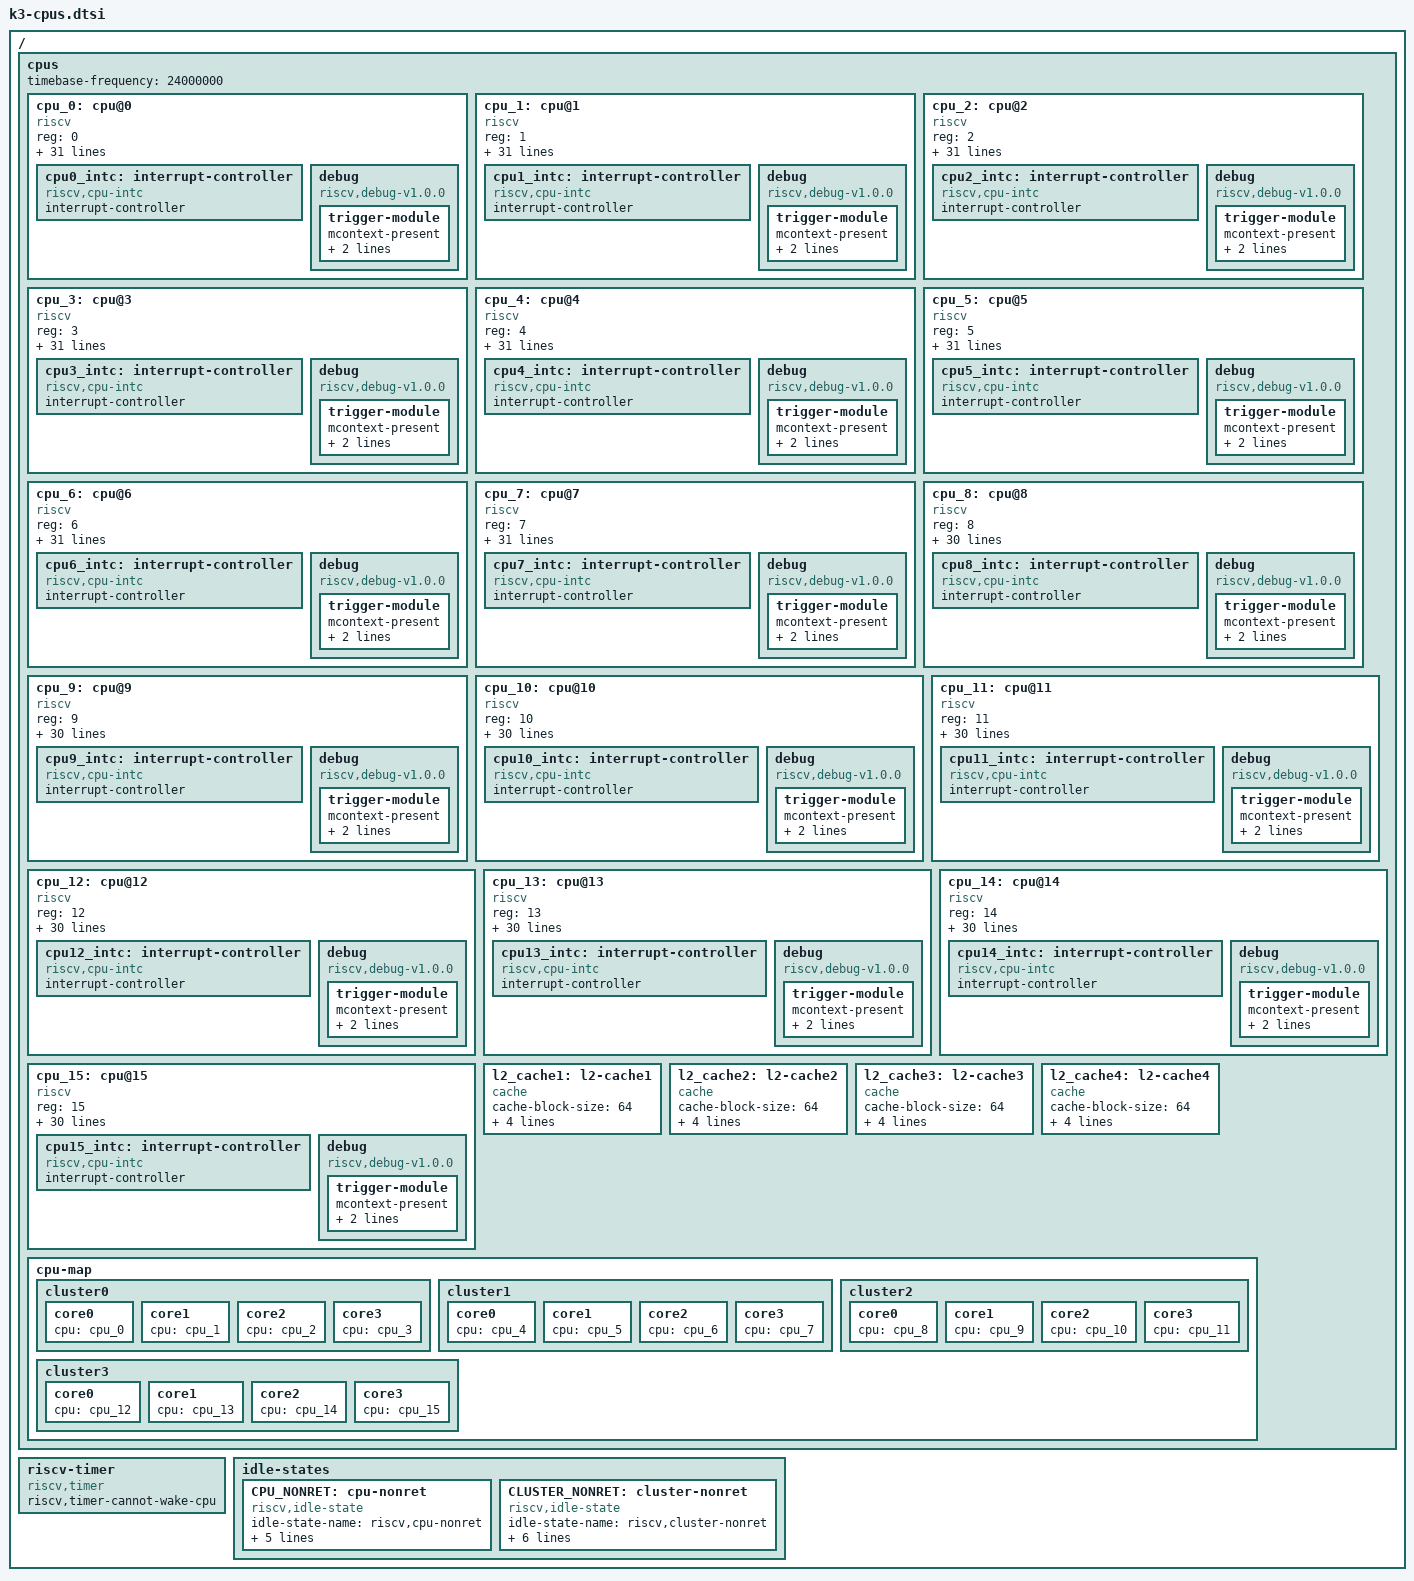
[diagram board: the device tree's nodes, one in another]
/ {
	cpus: cpus {
			#address-cells = <1>;
			#size-cells = <0>;
			timebase-frequency = <24000000>;

			cpu_0: cpu@0 {
				device_type = "cpu";
				reg = <0>;
				model = "Spacemit(R) X100";
				status = "okay";
				compatible = "riscv";
				riscv,isa = "rv64imafdcvh";
				riscv,isa-base = "rv64i";
				riscv,isa-extensions = "i", "m", "a", "f", "d", "c", "b", "v", "h",
						       "sdtrig",
						       "sha", "shcounterenw", "shgatpa", "shtvala",
						       "shvsatpa", "shvstvala", "shvstvecd", "smaia",
						       "smstateen", "ssaia", "ssccptr", "sscofpmf",
						       "sscounterenw", "ssnpm", "ssstateen", "sstc",
						       "sstvala", "sstvecd", "ssu64xl", "svade",
						       "svinval", "svnapot", "svpbmt", "za64rs",
						       "zawrs", "zba", "zbb", "zbc", "zbs", "zca",
						       "zcb", "zcd", "zcmop", "zfa", "zfbfmin",
						       "zfh", "zfhmin", "zicbom", "zicbop", "zicboz",
						       "ziccamoa", "ziccif", "zicclsm", "zicntr",
						       "zicond", "zicsr", "zifencei", "zihintntl",
						       "zihintpause", "zihpm", "zimop", "zkt", "zvbb",
						       "zvbc", "zvfbfmin", "zvfbfwma", "zvfh",
						       "zvfhmin", "zvkb", "zvkg", "zvkn", "zvknc",
						       "zvkned", "zvkng", "zvknha", "zvknhb", "zvks",
						       "zvksc", "zvksed", "zvksg", "zvksh", "zvkt";
				riscv,cbom-block-size = <64>;
				riscv,cboz-block-size = <64>;
				riscv,cbop-block-size = <64>;
				i-cache-block-size = <64>;
				i-cache-size = <65536>;
				i-cache-sets = <256>;
				d-cache-block-size = <64>;
				d-cache-size = <65536>;
				d-cache-sets = <256>;
				next-level-cache = <&l2_cache1>;
				cpu-idle-states = <&CPU_NONRET>, <&CLUSTER_NONRET>;
				mmu-type = "riscv,sv39";
				#cooling-cells = <2>;
				cpu0_intc: interrupt-controller {
					#interrupt-cells = <1>;
					compatible = "riscv,cpu-intc";
					interrupt-controller;
				};
				debug {
					compatible = "riscv,debug-v1.0.0";
					trigger-module {
						mcontext-present;
						hcontext-present;
						scontext-present;
					};
				};
			};

			cpu_1: cpu@1 {
				device_type = "cpu";
				reg = <1>;
				model = "Spacemit(R) X100";
				status = "okay";
				compatible = "riscv";
				riscv,isa = "rv64imafdcvh";
				riscv,isa-base = "rv64i";
				riscv,isa-extensions = "i", "m", "a", "f", "d", "c", "b", "v", "h",
						       "sdtrig",
						       "sha", "shcounterenw", "shgatpa", "shtvala",
						       "shvsatpa", "shvstvala", "shvstvecd", "smaia",
						       "smstateen", "ssaia", "ssccptr", "sscofpmf",
						       "sscounterenw", "ssnpm", "ssstateen", "sstc",
						       "sstvala", "sstvecd", "ssu64xl", "svade",
						       "svinval", "svnapot", "svpbmt", "za64rs",
						       "zawrs", "zba", "zbb", "zbc", "zbs", "zca",
						       "zcb", "zcd", "zcmop", "zfa", "zfbfmin",
						       "zfh", "zfhmin", "zicbom", "zicbop", "zicboz",
						       "ziccamoa", "ziccif", "zicclsm", "zicntr",
						       "zicond", "zicsr", "zifencei", "zihintntl",
						       "zihintpause", "zihpm", "zimop", "zkt", "zvbb",
						       "zvbc", "zvfbfmin", "zvfbfwma", "zvfh",
						       "zvfhmin", "zvkb", "zvkg", "zvkn", "zvknc",
						       "zvkned", "zvkng", "zvknha", "zvknhb", "zvks",
						       "zvksc", "zvksed", "zvksg", "zvksh", "zvkt";
				riscv,cbom-block-size = <64>;
				riscv,cboz-block-size = <64>;
				riscv,cbop-block-size = <64>;
				i-cache-block-size = <64>;
				i-cache-size = <65536>;
				i-cache-sets = <256>;
				d-cache-block-size = <64>;
				d-cache-size = <65536>;
				d-cache-sets = <256>;
				next-level-cache = <&l2_cache1>;
				cpu-idle-states = <&CPU_NONRET>, <&CLUSTER_NONRET>;
				mmu-type = "riscv,sv39";
				#cooling-cells = <2>;
				cpu1_intc: interrupt-controller {
					#interrupt-cells = <1>;
					compatible = "riscv,cpu-intc";
					interrupt-controller;
				};
				debug {
					compatible = "riscv,debug-v1.0.0";
					trigger-module {
						mcontext-present;
						hcontext-present;
						scontext-present;
					};
				};
			};

			cpu_2: cpu@2 {
				device_type = "cpu";
				reg = <2>;
				model = "Spacemit(R) X100";
				status = "okay";
				compatible = "riscv";
				riscv,isa = "rv64imafdcvh";
				riscv,isa-base = "rv64i";
				riscv,isa-extensions = "i", "m", "a", "f", "d", "c", "b", "v", "h",
						       "sdtrig",
						       "sha", "shcounterenw", "shgatpa", "shtvala",
						       "shvsatpa", "shvstvala", "shvstvecd", "smaia",
						       "smstateen", "ssaia", "ssccptr", "sscofpmf",
						       "sscounterenw", "ssnpm", "ssstateen", "sstc",
						       "sstvala", "sstvecd", "ssu64xl", "svade",
						       "svinval", "svnapot", "svpbmt", "za64rs",
						       "zawrs", "zba", "zbb", "zbc", "zbs", "zca",
						       "zcb", "zcd", "zcmop", "zfa", "zfbfmin",
						       "zfh", "zfhmin", "zicbom", "zicbop", "zicboz",
						       "ziccamoa", "ziccif", "zicclsm", "zicntr",
						       "zicond", "zicsr", "zifencei", "zihintntl",
						       "zihintpause", "zihpm", "zimop", "zkt", "zvbb",
						       "zvbc", "zvfbfmin", "zvfbfwma", "zvfh",
						       "zvfhmin", "zvkb", "zvkg", "zvkn", "zvknc",
						       "zvkned", "zvkng", "zvknha", "zvknhb", "zvks",
						       "zvksc", "zvksed", "zvksg", "zvksh", "zvkt";
				riscv,cbom-block-size = <64>;
				riscv,cboz-block-size = <64>;
				riscv,cbop-block-size = <64>;
				i-cache-block-size = <64>;
				i-cache-size = <65536>;
				i-cache-sets = <256>;
				d-cache-block-size = <64>;
				d-cache-size = <65536>;
				d-cache-sets = <256>;
				next-level-cache = <&l2_cache1>;
				cpu-idle-states = <&CPU_NONRET>, <&CLUSTER_NONRET>;
				mmu-type = "riscv,sv39";
				#cooling-cells = <2>;
				cpu2_intc: interrupt-controller {
					#interrupt-cells = <1>;
					compatible = "riscv,cpu-intc";
					interrupt-controller;
				};
				debug {
					compatible = "riscv,debug-v1.0.0";
					trigger-module {
						mcontext-present;
						hcontext-present;
						scontext-present;
					};
				};
			};

			cpu_3: cpu@3 {
				device_type = "cpu";
				reg = <3>;
				model = "Spacemit(R) X100";
				status = "okay";
				compatible = "riscv";
				riscv,isa = "rv64imafdcvh";
				riscv,isa-base = "rv64i";
				riscv,isa-extensions = "i", "m", "a", "f", "d", "c", "b", "v", "h",
						       "sdtrig",
						       "sha", "shcounterenw", "shgatpa", "shtvala",
						       "shvsatpa", "shvstvala", "shvstvecd", "smaia",
						       "smstateen", "ssaia", "ssccptr", "sscofpmf",
						       "sscounterenw", "ssnpm", "ssstateen", "sstc",
						       "sstvala", "sstvecd", "ssu64xl", "svade",
						       "svinval", "svnapot", "svpbmt", "za64rs",
						       "zawrs", "zba", "zbb", "zbc", "zbs", "zca",
						       "zcb", "zcd", "zcmop", "zfa", "zfbfmin",
						       "zfh", "zfhmin", "zicbom", "zicbop", "zicboz",
						       "ziccamoa", "ziccif", "zicclsm", "zicntr",
						       "zicond", "zicsr", "zifencei", "zihintntl",
						       "zihintpause", "zihpm", "zimop", "zkt", "zvbb",
						       "zvbc", "zvfbfmin", "zvfbfwma", "zvfh",
						       "zvfhmin", "zvkb", "zvkg", "zvkn", "zvknc",
						       "zvkned", "zvkng", "zvknha", "zvknhb", "zvks",
						       "zvksc", "zvksed", "zvksg", "zvksh", "zvkt";
				riscv,cbom-block-size = <64>;
				riscv,cboz-block-size = <64>;
				riscv,cbop-block-size = <64>;
				i-cache-block-size = <64>;
				i-cache-size = <65536>;
				i-cache-sets = <256>;
				d-cache-block-size = <64>;
				d-cache-size = <65536>;
				d-cache-sets = <256>;
				next-level-cache = <&l2_cache1>;
				cpu-idle-states = <&CPU_NONRET>, <&CLUSTER_NONRET>;
				mmu-type = "riscv,sv39";
				#cooling-cells = <2>;
				cpu3_intc: interrupt-controller {
					#interrupt-cells = <1>;
					compatible = "riscv,cpu-intc";
					interrupt-controller;
				};
				debug {
					compatible = "riscv,debug-v1.0.0";
					trigger-module {
						mcontext-present;
						hcontext-present;
						scontext-present;
					};
				};
			};

			cpu_4: cpu@4 {
				device_type = "cpu";
				reg = <4>;
				model = "Spacemit(R) X100";
				status = "okay";
				compatible = "riscv";
				riscv,isa = "rv64imafdcvh";
				riscv,isa-base = "rv64i";
				riscv,isa-extensions = "i", "m", "a", "f", "d", "c", "b", "v", "h",
						       "sdtrig",
						       "sha", "shcounterenw", "shgatpa", "shtvala",
						       "shvsatpa", "shvstvala", "shvstvecd", "smaia",
						       "smstateen", "ssaia", "ssccptr", "sscofpmf",
						       "sscounterenw", "ssnpm", "ssstateen", "sstc",
						       "sstvala", "sstvecd", "ssu64xl", "svade",
						       "svinval", "svnapot", "svpbmt", "za64rs",
						       "zawrs", "zba", "zbb", "zbc", "zbs", "zca",
						       "zcb", "zcd", "zcmop", "zfa", "zfbfmin",
						       "zfh", "zfhmin", "zicbom", "zicbop", "zicboz",
						       "ziccamoa", "ziccif", "zicclsm", "zicntr",
						       "zicond", "zicsr", "zifencei", "zihintntl",
						       "zihintpause", "zihpm", "zimop", "zkt", "zvbb",
						       "zvbc", "zvfbfmin", "zvfbfwma", "zvfh",
						       "zvfhmin", "zvkb", "zvkg", "zvkn", "zvknc",
						       "zvkned", "zvkng", "zvknha", "zvknhb", "zvks",
						       "zvksc", "zvksed", "zvksg", "zvksh", "zvkt";
				riscv,cbom-block-size = <64>;
				riscv,cboz-block-size = <64>;
				riscv,cbop-block-size = <64>;
				i-cache-block-size = <64>;
				i-cache-size = <65536>;
				i-cache-sets = <256>;
				d-cache-block-size = <64>;
				d-cache-size = <65536>;
				d-cache-sets = <256>;
				next-level-cache = <&l2_cache2>;
				cpu-idle-states = <&CPU_NONRET>, <&CLUSTER_NONRET>;
				mmu-type = "riscv,sv39";
				#cooling-cells = <2>;
				cpu4_intc: interrupt-controller {
					#interrupt-cells = <1>;
					compatible = "riscv,cpu-intc";
					interrupt-controller;
				};
				debug {
					compatible = "riscv,debug-v1.0.0";
					trigger-module {
						mcontext-present;
						hcontext-present;
						scontext-present;
					};
				};
			};

			cpu_5: cpu@5 {
				device_type = "cpu";
				reg = <5>;
				model = "Spacemit(R) X100";
				status = "okay";
				compatible = "riscv";
				riscv,isa = "rv64imafdcvh";
				riscv,isa-base = "rv64i";
				riscv,isa-extensions = "i", "m", "a", "f", "d", "c", "b", "v", "h",
						       "sdtrig",
						       "sha", "shcounterenw", "shgatpa", "shtvala",
						       "shvsatpa", "shvstvala", "shvstvecd", "smaia",
						       "smstateen", "ssaia", "ssccptr", "sscofpmf",
						       "sscounterenw", "ssnpm", "ssstateen", "sstc",
						       "sstvala", "sstvecd", "ssu64xl", "svade",
						       "svinval", "svnapot", "svpbmt", "za64rs",
						       "zawrs", "zba", "zbb", "zbc", "zbs", "zca",
						       "zcb", "zcd", "zcmop", "zfa", "zfbfmin",
						       "zfh", "zfhmin", "zicbom", "zicbop", "zicboz",
						       "ziccamoa", "ziccif", "zicclsm", "zicntr",
						       "zicond", "zicsr", "zifencei", "zihintntl",
						       "zihintpause", "zihpm", "zimop", "zkt", "zvbb",
						       "zvbc", "zvfbfmin", "zvfbfwma", "zvfh",
						       "zvfhmin", "zvkb", "zvkg", "zvkn", "zvknc",
						       "zvkned", "zvkng", "zvknha", "zvknhb", "zvks",
						       "zvksc", "zvksed", "zvksg", "zvksh", "zvkt";
				riscv,cbom-block-size = <64>;
				riscv,cboz-block-size = <64>;
				riscv,cbop-block-size = <64>;
				i-cache-block-size = <64>;
				i-cache-size = <65536>;
				i-cache-sets = <256>;
				d-cache-block-size = <64>;
				d-cache-size = <65536>;
				d-cache-sets = <256>;
				next-level-cache = <&l2_cache2>;
				cpu-idle-states = <&CPU_NONRET>, <&CLUSTER_NONRET>;
				mmu-type = "riscv,sv39";
				#cooling-cells = <2>;
				cpu5_intc: interrupt-controller {
					#interrupt-cells = <1>;
					compatible = "riscv,cpu-intc";
					interrupt-controller;
				};
				debug {
					compatible = "riscv,debug-v1.0.0";
					trigger-module {
						mcontext-present;
						hcontext-present;
						scontext-present;
					};
				};
			};

			cpu_6: cpu@6 {
				device_type = "cpu";
				reg = <6>;
				model = "Spacemit(R) X100";
				status = "okay";
				compatible = "riscv";
				riscv,isa = "rv64imafdcvh";
				riscv,isa-base = "rv64i";
				riscv,isa-extensions = "i", "m", "a", "f", "d", "c", "b", "v", "h",
						       "sdtrig",
						       "sha", "shcounterenw", "shgatpa", "shtvala",
						       "shvsatpa", "shvstvala", "shvstvecd", "smaia",
						       "smstateen", "ssaia", "ssccptr", "sscofpmf",
						       "sscounterenw", "ssnpm", "ssstateen", "sstc",
						       "sstvala", "sstvecd", "ssu64xl", "svade",
						       "svinval", "svnapot", "svpbmt", "za64rs",
						       "zawrs", "zba", "zbb", "zbc", "zbs", "zca",
						       "zcb", "zcd", "zcmop", "zfa", "zfbfmin",
						       "zfh", "zfhmin", "zicbom", "zicbop", "zicboz",
						       "ziccamoa", "ziccif", "zicclsm", "zicntr",
						       "zicond", "zicsr", "zifencei", "zihintntl",
						       "zihintpause", "zihpm", "zimop", "zkt", "zvbb",
						       "zvbc", "zvfbfmin", "zvfbfwma", "zvfh",
						       "zvfhmin", "zvkb", "zvkg", "zvkn", "zvknc",
						       "zvkned", "zvkng", "zvknha", "zvknhb", "zvks",
						       "zvksc", "zvksed", "zvksg", "zvksh", "zvkt";
				riscv,cbom-block-size = <64>;
				riscv,cboz-block-size = <64>;
				riscv,cbop-block-size = <64>;
				i-cache-block-size = <64>;
				i-cache-size = <65536>;
				i-cache-sets = <256>;
				d-cache-block-size = <64>;
				d-cache-size = <65536>;
				d-cache-sets = <256>;
				next-level-cache = <&l2_cache2>;
				cpu-idle-states = <&CPU_NONRET>, <&CLUSTER_NONRET>;
				mmu-type = "riscv,sv39";
				#cooling-cells = <2>;
				cpu6_intc: interrupt-controller {
					#interrupt-cells = <1>;
					compatible = "riscv,cpu-intc";
					interrupt-controller;
				};
				debug {
					compatible = "riscv,debug-v1.0.0";
					trigger-module {
						mcontext-present;
						hcontext-present;
						scontext-present;
					};
				};
			};

			cpu_7: cpu@7 {
				device_type = "cpu";
				reg = <7>;
				model = "Spacemit(R) X100";
				status = "okay";
				compatible = "riscv";
				riscv,isa = "rv64imafdcvh";
				riscv,isa-base = "rv64i";
				riscv,isa-extensions = "i", "m", "a", "f", "d", "c", "b", "v", "h",
						       "sdtrig",
						       "sha", "shcounterenw", "shgatpa", "shtvala",
						       "shvsatpa", "shvstvala", "shvstvecd", "smaia",
						       "smstateen", "ssaia", "ssccptr", "sscofpmf",
						       "sscounterenw", "ssnpm", "ssstateen", "sstc",
						       "sstvala", "sstvecd", "ssu64xl", "svade",
						       "svinval", "svnapot", "svpbmt", "za64rs",
						       "zawrs", "zba", "zbb", "zbc", "zbs", "zca",
						       "zcb", "zcd", "zcmop", "zfa", "zfbfmin",
						       "zfh", "zfhmin", "zicbom", "zicbop", "zicboz",
						       "ziccamoa", "ziccif", "zicclsm", "zicntr",
						       "zicond", "zicsr", "zifencei", "zihintntl",
						       "zihintpause", "zihpm", "zimop", "zkt", "zvbb",
						       "zvbc", "zvfbfmin", "zvfbfwma", "zvfh",
						       "zvfhmin", "zvkb", "zvkg", "zvkn", "zvknc",
						       "zvkned", "zvkng", "zvknha", "zvknhb", "zvks",
						       "zvksc", "zvksed", "zvksg", "zvksh", "zvkt";
				riscv,cbom-block-size = <64>;
				riscv,cboz-block-size = <64>;
				riscv,cbop-block-size = <64>;
				i-cache-block-size = <64>;
				i-cache-size = <65536>;
				i-cache-sets = <256>;
				d-cache-block-size = <64>;
				d-cache-size = <65536>;
				d-cache-sets = <256>;
				next-level-cache = <&l2_cache2>;
				cpu-idle-states = <&CPU_NONRET>, <&CLUSTER_NONRET>;
				mmu-type = "riscv,sv39";
				#cooling-cells = <2>;
				cpu7_intc: interrupt-controller {
					#interrupt-cells = <1>;
					compatible = "riscv,cpu-intc";
					interrupt-controller;
				};
				debug {
					compatible = "riscv,debug-v1.0.0";
					trigger-module {
						mcontext-present;
						hcontext-present;
						scontext-present;
					};
				};
			};

			cpu_8: cpu@8 {
				device_type = "cpu";
				reg = <8>;
				model = "Spacemit(R) A100";
				status = "okay";
				compatible = "riscv";
				cpu-ai = "true";
				riscv,isa = "rv64imafdcv";
				riscv,isa-base = "rv64i";
				riscv,isa-extensions = "i", "m", "a", "f", "d", "c", "b", "v",
						       "sdtrig", "smaia",
						       "smstateen", "ssaia", "ssccptr", "sscofpmf",
						       "sscounterenw", "ssnpm", "ssstateen", "sstc",
						       "sstvala", "sstvecd", "ssu64xl", "svade",
						       "svinval", "svnapot", "svpbmt", "za64rs",
						       "zawrs", "zba", "zbb", "zbc", "zbs", "zca",
						       "zcb", "zcd", "zcmop", "zfa", "zfbfmin",
						       "zfh", "zfhmin", "zicbom", "zicbop", "zicboz",
						       "ziccamoa", "ziccif", "zicclsm", "zicntr",
						       "zicond", "zicsr", "zifencei", "zihintntl",
						       "zihintpause", "zihpm", "zimop", "zkt", "zvbb",
						       "zvbc", "zvfbfmin", "zvfbfwma", "zvfh",
						       "zvfhmin", "zvkb", "zvkg", "zvkn", "zvknc",
						       "zvkned", "zvkng", "zvknha", "zvknhb", "zvks",
						       "zvksc", "zvksed", "zvksg", "zvksh", "zvkt";
				riscv,cbom-block-size = <64>;
				riscv,cboz-block-size = <64>;
				riscv,cbop-block-size = <64>;
				i-cache-block-size = <64>;
				i-cache-size = <65536>;
				i-cache-sets = <256>;
				d-cache-block-size = <64>;
				d-cache-size = <65536>;
				d-cache-sets = <256>;
				next-level-cache = <&l2_cache3>;
				cpu-idle-states = <&CPU_NONRET>, <&CLUSTER_NONRET>;
				mmu-type = "riscv,sv39";
				#cooling-cells = <2>;
				cpu8_intc: interrupt-controller {
					#interrupt-cells = <1>;
					compatible = "riscv,cpu-intc";
					interrupt-controller;
				};
				debug {
					compatible = "riscv,debug-v1.0.0";
					trigger-module {
						mcontext-present;
						hcontext-present;
						scontext-present;
					};
				};
			};

			cpu_9: cpu@9 {
				device_type = "cpu";
				reg = <9>;
				model = "Spacemit(R) A100";
				status = "okay";
				compatible = "riscv";
				cpu-ai = "true";
				riscv,isa = "rv64imafdcv";
				riscv,isa-base = "rv64i";
				riscv,isa-extensions = "i", "m", "a", "f", "d", "c", "b", "v",
						       "sdtrig", "smaia",
						       "smstateen", "ssaia", "ssccptr", "sscofpmf",
						       "sscounterenw", "ssnpm", "ssstateen", "sstc",
						       "sstvala", "sstvecd", "ssu64xl", "svade",
						       "svinval", "svnapot", "svpbmt", "za64rs",
						       "zawrs", "zba", "zbb", "zbc", "zbs", "zca",
						       "zcb", "zcd", "zcmop", "zfa", "zfbfmin",
						       "zfh", "zfhmin", "zicbom", "zicbop", "zicboz",
						       "ziccamoa", "ziccif", "zicclsm", "zicntr",
						       "zicond", "zicsr", "zifencei", "zihintntl",
						       "zihintpause", "zihpm", "zimop", "zkt", "zvbb",
						       "zvbc", "zvfbfmin", "zvfbfwma", "zvfh",
						       "zvfhmin", "zvkb", "zvkg", "zvkn", "zvknc",
						       "zvkned", "zvkng", "zvknha", "zvknhb", "zvks",
						       "zvksc", "zvksed", "zvksg", "zvksh", "zvkt";
				riscv,cbom-block-size = <64>;
				riscv,cboz-block-size = <64>;
				riscv,cbop-block-size = <64>;
				i-cache-block-size = <64>;
				i-cache-size = <65536>;
				i-cache-sets = <256>;
				d-cache-block-size = <64>;
				d-cache-size = <65536>;
				d-cache-sets = <256>;
				next-level-cache = <&l2_cache3>;
				cpu-idle-states = <&CPU_NONRET>, <&CLUSTER_NONRET>;
				mmu-type = "riscv,sv39";
				#cooling-cells = <2>;
				cpu9_intc: interrupt-controller {
					#interrupt-cells = <1>;
					compatible = "riscv,cpu-intc";
					interrupt-controller;
				};
				debug {
					compatible = "riscv,debug-v1.0.0";
					trigger-module {
						mcontext-present;
						hcontext-present;
						scontext-present;
					};
				};
			};

			cpu_10: cpu@10 {
				device_type = "cpu";
				reg = <10>;
				model = "Spacemit(R) A100";
				status = "okay";
				compatible = "riscv";
				cpu-ai = "true";
				riscv,isa = "rv64imafdcv";
				riscv,isa-base = "rv64i";
				riscv,isa-extensions = "i", "m", "a", "f", "d", "c", "b", "v",
						       "sdtrig", "smaia",
						       "smstateen", "ssaia", "ssccptr", "sscofpmf",
						       "sscounterenw", "ssnpm", "ssstateen", "sstc",
						       "sstvala", "sstvecd", "ssu64xl", "svade",
						       "svinval", "svnapot", "svpbmt", "za64rs",
						       "zawrs", "zba", "zbb", "zbc", "zbs", "zca",
						       "zcb", "zcd", "zcmop", "zfa", "zfbfmin",
						       "zfh", "zfhmin", "zicbom", "zicbop", "zicboz",
						       "ziccamoa", "ziccif", "zicclsm", "zicntr",
						       "zicond", "zicsr", "zifencei", "zihintntl",
						       "zihintpause", "zihpm", "zimop", "zkt", "zvbb",
						       "zvbc", "zvfbfmin", "zvfbfwma", "zvfh",
						       "zvfhmin", "zvkb", "zvkg", "zvkn", "zvknc",
						       "zvkned", "zvkng", "zvknha", "zvknhb", "zvks",
						       "zvksc", "zvksed", "zvksg", "zvksh", "zvkt";
				riscv,cbom-block-size = <64>;
				riscv,cboz-block-size = <64>;
				riscv,cbop-block-size = <64>;
				i-cache-block-size = <64>;
				i-cache-size = <65536>;
				i-cache-sets = <256>;
				d-cache-block-size = <64>;
				d-cache-size = <65536>;
				d-cache-sets = <256>;
				next-level-cache = <&l2_cache3>;
				cpu-idle-states = <&CPU_NONRET>, <&CLUSTER_NONRET>;
				mmu-type = "riscv,sv39";
				#cooling-cells = <2>;
				cpu10_intc: interrupt-controller {
					#interrupt-cells = <1>;
					compatible = "riscv,cpu-intc";
					interrupt-controller;
				};
				debug {
					compatible = "riscv,debug-v1.0.0";
					trigger-module {
						mcontext-present;
						hcontext-present;
						scontext-present;
					};
				};
			};

			cpu_11: cpu@11 {
				device_type = "cpu";
				reg = <11>;
				model = "Spacemit(R) A100";
				status = "okay";
				compatible = "riscv";
				cpu-ai = "true";
				riscv,isa = "rv64imafdcv";
				riscv,isa-base = "rv64i";
				riscv,isa-extensions = "i", "m", "a", "f", "d", "c", "b", "v",
						       "sdtrig", "smaia",
						       "smstateen", "ssaia", "ssccptr", "sscofpmf",
						       "sscounterenw", "ssnpm", "ssstateen", "sstc",
						       "sstvala", "sstvecd", "ssu64xl", "svade",
						       "svinval", "svnapot", "svpbmt", "za64rs",
						       "zawrs", "zba", "zbb", "zbc", "zbs", "zca",
						       "zcb", "zcd", "zcmop", "zfa", "zfbfmin",
						       "zfh", "zfhmin", "zicbom", "zicbop", "zicboz",
						       "ziccamoa", "ziccif", "zicclsm", "zicntr",
						       "zicond", "zicsr", "zifencei", "zihintntl",
						       "zihintpause", "zihpm", "zimop", "zkt", "zvbb",
						       "zvbc", "zvfbfmin", "zvfbfwma", "zvfh",
						       "zvfhmin", "zvkb", "zvkg", "zvkn", "zvknc",
						       "zvkned", "zvkng", "zvknha", "zvknhb", "zvks",
						       "zvksc", "zvksed", "zvksg", "zvksh", "zvkt";
				riscv,cbom-block-size = <64>;
				riscv,cboz-block-size = <64>;
				riscv,cbop-block-size = <64>;
				i-cache-block-size = <64>;
				i-cache-size = <65536>;
				i-cache-sets = <256>;
				d-cache-block-size = <64>;
				d-cache-size = <65536>;
				d-cache-sets = <256>;
				next-level-cache = <&l2_cache3>;
				cpu-idle-states = <&CPU_NONRET>, <&CLUSTER_NONRET>;
				mmu-type = "riscv,sv39";
				#cooling-cells = <2>;
				cpu11_intc: interrupt-controller {
					#interrupt-cells = <1>;
					compatible = "riscv,cpu-intc";
					interrupt-controller;
				};
				debug {
					compatible = "riscv,debug-v1.0.0";
					trigger-module {
						mcontext-present;
						hcontext-present;
						scontext-present;
					};
				};
			};

			cpu_12: cpu@12 {
				device_type = "cpu";
				reg = <12>;
				model = "Spacemit(R) A100";
				status = "okay";
				compatible = "riscv";
				cpu-ai = "true";
				riscv,isa = "rv64imafdcv";
				riscv,isa-base = "rv64i";
				riscv,isa-extensions = "i", "m", "a", "f", "d", "c", "b", "v",
						       "sdtrig", "smaia",
						       "smstateen", "ssaia", "ssccptr", "sscofpmf",
						       "sscounterenw", "ssnpm", "ssstateen", "sstc",
						       "sstvala", "sstvecd", "ssu64xl", "svade",
						       "svinval", "svnapot", "svpbmt", "za64rs",
						       "zawrs", "zba", "zbb", "zbc", "zbs", "zca",
						       "zcb", "zcd", "zcmop", "zfa", "zfbfmin",
						       "zfh", "zfhmin", "zicbom", "zicbop", "zicboz",
						       "ziccamoa", "ziccif", "zicclsm", "zicntr",
						       "zicond", "zicsr", "zifencei", "zihintntl",
						       "zihintpause", "zihpm", "zimop", "zkt", "zvbb",
						       "zvbc", "zvfbfmin", "zvfbfwma", "zvfh",
						       "zvfhmin", "zvkb", "zvkg", "zvkn", "zvknc",
						       "zvkned", "zvkng", "zvknha", "zvknhb", "zvks",
						       "zvksc", "zvksed", "zvksg", "zvksh", "zvkt";
				riscv,cbom-block-size = <64>;
				riscv,cboz-block-size = <64>;
				riscv,cbop-block-size = <64>;
				i-cache-block-size = <64>;
				i-cache-size = <65536>;
				i-cache-sets = <256>;
				d-cache-block-size = <64>;
				d-cache-size = <65536>;
				d-cache-sets = <256>;
				next-level-cache = <&l2_cache4>;
				cpu-idle-states = <&CPU_NONRET>, <&CLUSTER_NONRET>;
				mmu-type = "riscv,sv39";
				#cooling-cells = <2>;
				cpu12_intc: interrupt-controller {
					#interrupt-cells = <1>;
					compatible = "riscv,cpu-intc";
					interrupt-controller;
				};
				debug {
					compatible = "riscv,debug-v1.0.0";
					trigger-module {
						mcontext-present;
						hcontext-present;
						scontext-present;
					};
				};
			};

			cpu_13: cpu@13 {
				device_type = "cpu";
				reg = <13>;
				model = "Spacemit(R) A100";
				status = "okay";
				compatible = "riscv";
				cpu-ai = "true";
				riscv,isa = "rv64imafdcv";
				riscv,isa-base = "rv64i";
				riscv,isa-extensions = "i", "m", "a", "f", "d", "c", "b", "v",
						       "sdtrig", "smaia",
						       "smstateen", "ssaia", "ssccptr", "sscofpmf",
						       "sscounterenw", "ssnpm", "ssstateen", "sstc",
						       "sstvala", "sstvecd", "ssu64xl", "svade",
						       "svinval", "svnapot", "svpbmt", "za64rs",
						       "zawrs", "zba", "zbb", "zbc", "zbs", "zca",
						       "zcb", "zcd", "zcmop", "zfa", "zfbfmin",
						       "zfh", "zfhmin", "zicbom", "zicbop", "zicboz",
						       "ziccamoa", "ziccif", "zicclsm", "zicntr",
						       "zicond", "zicsr", "zifencei", "zihintntl",
						       "zihintpause", "zihpm", "zimop", "zkt", "zvbb",
						       "zvbc", "zvfbfmin", "zvfbfwma", "zvfh",
						       "zvfhmin", "zvkb", "zvkg", "zvkn", "zvknc",
						       "zvkned", "zvkng", "zvknha", "zvknhb", "zvks",
						       "zvksc", "zvksed", "zvksg", "zvksh", "zvkt";
				riscv,cbom-block-size = <64>;
				riscv,cboz-block-size = <64>;
				riscv,cbop-block-size = <64>;
				i-cache-block-size = <64>;
				i-cache-size = <65536>;
				i-cache-sets = <256>;
				d-cache-block-size = <64>;
				d-cache-size = <65536>;
				d-cache-sets = <256>;
				next-level-cache = <&l2_cache4>;
				cpu-idle-states = <&CPU_NONRET>, <&CLUSTER_NONRET>;
				mmu-type = "riscv,sv39";
				#cooling-cells = <2>;
				cpu13_intc: interrupt-controller {
					#interrupt-cells = <1>;
					compatible = "riscv,cpu-intc";
					interrupt-controller;
				};
				debug {
					compatible = "riscv,debug-v1.0.0";
					trigger-module {
						mcontext-present;
						hcontext-present;
						scontext-present;
					};
				};
			};

			cpu_14: cpu@14 {
				device_type = "cpu";
				reg = <14>;
				model = "Spacemit(R) A100";
				status = "okay";
				compatible = "riscv";
				cpu-ai = "true";
				riscv,isa = "rv64imafdcv";
				riscv,isa-base = "rv64i";
				riscv,isa-extensions = "i", "m", "a", "f", "d", "c", "b", "v",
						       "sdtrig", "smaia",
						       "smstateen", "ssaia", "ssccptr", "sscofpmf",
						       "sscounterenw", "ssnpm", "ssstateen", "sstc",
						       "sstvala", "sstvecd", "ssu64xl", "svade",
						       "svinval", "svnapot", "svpbmt", "za64rs",
						       "zawrs", "zba", "zbb", "zbc", "zbs", "zca",
						       "zcb", "zcd", "zcmop", "zfa", "zfbfmin",
						       "zfh", "zfhmin", "zicbom", "zicbop", "zicboz",
						       "ziccamoa", "ziccif", "zicclsm", "zicntr",
						       "zicond", "zicsr", "zifencei", "zihintntl",
						       "zihintpause", "zihpm", "zimop", "zkt", "zvbb",
						       "zvbc", "zvfbfmin", "zvfbfwma", "zvfh",
						       "zvfhmin", "zvkb", "zvkg", "zvkn", "zvknc",
						       "zvkned", "zvkng", "zvknha", "zvknhb", "zvks",
						       "zvksc", "zvksed", "zvksg", "zvksh", "zvkt";
				riscv,cbom-block-size = <64>;
				riscv,cboz-block-size = <64>;
				riscv,cbop-block-size = <64>;
				i-cache-block-size = <64>;
				i-cache-size = <65536>;
				i-cache-sets = <256>;
				d-cache-block-size = <64>;
				d-cache-size = <65536>;
				d-cache-sets = <256>;
				next-level-cache = <&l2_cache4>;
				cpu-idle-states = <&CPU_NONRET>, <&CLUSTER_NONRET>;
				mmu-type = "riscv,sv39";
				#cooling-cells = <2>;
				cpu14_intc: interrupt-controller {
					#interrupt-cells = <1>;
					compatible = "riscv,cpu-intc";
					interrupt-controller;
				};
				debug {
					compatible = "riscv,debug-v1.0.0";
					trigger-module {
						mcontext-present;
						hcontext-present;
						scontext-present;
					};
				};
			};

			cpu_15: cpu@15 {
				device_type = "cpu";
				reg = <15>;
				model = "Spacemit(R) A100";
				status = "okay";
				compatible = "riscv";
				cpu-ai = "true";
				riscv,isa = "rv64imafdcv";
				riscv,isa-base = "rv64i";
				riscv,isa-extensions = "i", "m", "a", "f", "d", "c", "b", "v",
						       "sdtrig", "smaia",
						       "smstateen", "ssaia", "ssccptr", "sscofpmf",
						       "sscounterenw", "ssnpm", "ssstateen", "sstc",
						       "sstvala", "sstvecd", "ssu64xl", "svade",
						       "svinval", "svnapot", "svpbmt", "za64rs",
						       "zawrs", "zba", "zbb", "zbc", "zbs", "zca",
						       "zcb", "zcd", "zcmop", "zfa", "zfbfmin",
						       "zfh", "zfhmin", "zicbom", "zicbop", "zicboz",
						       "ziccamoa", "ziccif", "zicclsm", "zicntr",
						       "zicond", "zicsr", "zifencei", "zihintntl",
						       "zihintpause", "zihpm", "zimop", "zkt", "zvbb",
						       "zvbc", "zvfbfmin", "zvfbfwma", "zvfh",
						       "zvfhmin", "zvkb", "zvkg", "zvkn", "zvknc",
						       "zvkned", "zvkng", "zvknha", "zvknhb", "zvks",
						       "zvksc", "zvksed", "zvksg", "zvksh", "zvkt";
				riscv,cbom-block-size = <64>;
				riscv,cboz-block-size = <64>;
				riscv,cbop-block-size = <64>;
				i-cache-block-size = <64>;
				i-cache-size = <65536>;
				i-cache-sets = <256>;
				d-cache-block-size = <64>;
				d-cache-size = <65536>;
				d-cache-sets = <256>;
				next-level-cache = <&l2_cache4>;
				cpu-idle-states = <&CPU_NONRET>, <&CLUSTER_NONRET>;
				mmu-type = "riscv,sv39";
				#cooling-cells = <2>;
				cpu15_intc: interrupt-controller {
					#interrupt-cells = <1>;
					compatible = "riscv,cpu-intc";
					interrupt-controller;
				};
				debug {
					compatible = "riscv,debug-v1.0.0";
					trigger-module {
						mcontext-present;
						hcontext-present;
						scontext-present;
					};
				};
			};

			l2_cache1: l2-cache1 {
				compatible = "cache";
				cache-block-size = <64>;
				cache-level = <2>;
				cache-size = <4194304>;
				cache-sets = <4096>;
				cache-unified;
			};

			l2_cache2: l2-cache2 {
				compatible = "cache";
				cache-block-size = <64>;
				cache-level = <2>;
				cache-size = <4194304>;
				cache-sets = <4096>;
				cache-unified;
			};

			l2_cache3: l2-cache3 {
				compatible = "cache";
				cache-block-size = <64>;
				cache-level = <2>;
				cache-size = <1048576>;
				cache-sets = <1024>;
				cache-unified;
			};

			l2_cache4: l2-cache4 {
				compatible = "cache";
				cache-block-size = <64>;
				cache-level = <2>;
				cache-size = <1048576>;
				cache-sets = <1024>;
				cache-unified;
			};

			cpu-map {
				cluster0 {
					core0 {
						cpu = <&cpu_0>;
					};

					core1 {
						cpu = <&cpu_1>;
					};

					core2 {
						cpu = <&cpu_2>;
					};

					core3 {
						cpu = <&cpu_3>;
					};
				};
				cluster1 {
					core0 {
						cpu = <&cpu_4>;
					};

					core1 {
						cpu = <&cpu_5>;
					};

					core2 {
						cpu = <&cpu_6>;
					};

					core3 {
						cpu = <&cpu_7>;
					};
				};
				cluster2 {
					core0 {
						cpu = <&cpu_8>;
					};

					core1 {
						cpu = <&cpu_9>;
					};

					core2 {
						cpu = <&cpu_10>;
					};

					core3 {
						cpu = <&cpu_11>;
					};
				};
				cluster3 {
					core0 {
						cpu = <&cpu_12>;
					};

					core1 {
						cpu = <&cpu_13>;
					};

					core2 {
						cpu = <&cpu_14>;
					};

					core3 {
						cpu = <&cpu_15>;
					};
				};
			};
	};

	riscv-timer {
		compatible = "riscv,timer";
		riscv,timer-cannot-wake-cpu;
	};

	idle-states {
		CPU_NONRET: cpu-nonret {
			compatible = "riscv,idle-state";
			idle-state-name = "riscv,cpu-nonret";
			riscv,sbi-suspend-param = <0x90000000>;
			local-timer-stop;
			entry-latency-us = <200>;
			exit-latency-us = <500>;
			min-residency-us = <950>;
		};

		CLUSTER_NONRET: cluster-nonret {
			compatible = "riscv,idle-state";
			idle-state-name = "riscv,cluster-nonret";
			riscv,sbi-suspend-param = <0x91000000>;
			local-timer-stop;
			entry-latency-us = <600>;
			exit-latency-us = <1100>;
			min-residency-us = <2700>;
			wakeup-latency-us = <1500>;
		};
	};
};
